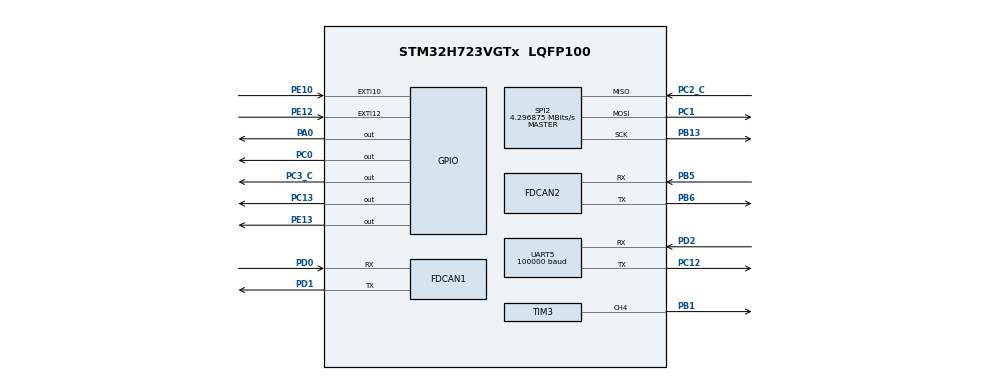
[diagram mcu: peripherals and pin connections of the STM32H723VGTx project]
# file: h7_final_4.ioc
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CORTEX_M7.default_mode_Activation=0
Dma.Request0=UART5_RX
Dma.Request1=SPI2_TX
Dma.Request2=SPI2_RX
Dma.SPI2_RX.2.Direction=DMA_PERIPH_TO_MEMORY
Dma.SPI2_RX.2.EventEnable=DISABLE
Dma.SPI2_RX.2.FIFOMode=DMA_FIFOMODE_DISABLE
Dma.SPI2_RX.2.Instance=DMA1_Stream2
Dma.SPI2_RX.2.MemDataAlignment=DMA_MDATAALIGN_BYTE
Dma.SPI2_RX.2.MemInc=DMA_MINC_ENABLE
Dma.SPI2_RX.2.Mode=DMA_NORMAL
Dma.SPI2_RX.2.PeriphDataAlignment=DMA_PDATAALIGN_BYTE
Dma.SPI2_RX.2.PeriphInc=DMA_PINC_DISABLE
Dma.SPI2_RX.2.Polarity=HAL_DMAMUX_REQ_GEN_RISING
Dma.SPI2_RX.2.Priority=DMA_PRIORITY_LOW
Dma.SPI2_RX.2.RequestNumber=1
Dma.SPI2_RX.2.SignalID=NONE
Dma.SPI2_RX.2.SyncEnable=DISABLE
Dma.SPI2_RX.2.SyncPolarity=HAL_DMAMUX_SYNC_NO_EVENT
Dma.SPI2_RX.2.SyncRequestNumber=1
Dma.SPI2_RX.2.SyncSignalID=NONE
Dma.SPI2_TX.1.Direction=DMA_MEMORY_TO_PERIPH
Dma.SPI2_TX.1.EventEnable=DISABLE
Dma.SPI2_TX.1.FIFOMode=DMA_FIFOMODE_DISABLE
Dma.SPI2_TX.1.Instance=DMA1_Stream1
Dma.SPI2_TX.1.MemDataAlignment=DMA_MDATAALIGN_BYTE
Dma.SPI2_TX.1.MemInc=DMA_MINC_ENABLE
Dma.SPI2_TX.1.Mode=DMA_NORMAL
Dma.SPI2_TX.1.PeriphDataAlignment=DMA_PDATAALIGN_BYTE
Dma.SPI2_TX.1.PeriphInc=DMA_PINC_DISABLE
Dma.SPI2_TX.1.Polarity=HAL_DMAMUX_REQ_GEN_RISING
Dma.SPI2_TX.1.Priority=DMA_PRIORITY_LOW
Dma.SPI2_TX.1.RequestNumber=1
Dma.SPI2_TX.1.SignalID=NONE
Dma.SPI2_TX.1.SyncEnable=DISABLE
Dma.SPI2_TX.1.SyncPolarity=HAL_DMAMUX_SYNC_NO_EVENT
Dma.SPI2_TX.1.SyncRequestNumber=1
Dma.SPI2_TX.1.SyncSignalID=NONE
Dma.UART5_RX.0.Direction=DMA_PERIPH_TO_MEMORY
Dma.UART5_RX.0.EventEnable=DISABLE
Dma.UART5_RX.0.FIFOMode=DMA_FIFOMODE_DISABLE
Dma.UART5_RX.0.Instance=DMA1_Stream0
Dma.UART5_RX.0.MemDataAlignment=DMA_MDATAALIGN_BYTE
Dma.UART5_RX.0.MemInc=DMA_MINC_ENABLE
Dma.UART5_RX.0.Mode=DMA_NORMAL
Dma.UART5_RX.0.PeriphDataAlignment=DMA_PDATAALIGN_BYTE
Dma.UART5_RX.0.PeriphInc=DMA_PINC_DISABLE
Dma.UART5_RX.0.Polarity=HAL_DMAMUX_REQ_GEN_RISING
Dma.UART5_RX.0.Priority=DMA_PRIORITY_LOW
Dma.UART5_RX.0.RequestNumber=1
Dma.UART5_RX.0.SignalID=NONE
Dma.UART5_RX.0.SyncEnable=DISABLE
Dma.UART5_RX.0.SyncPolarity=HAL_DMAMUX_SYNC_NO_EVENT
Dma.UART5_RX.0.SyncRequestNumber=1
Dma.UART5_RX.0.SyncSignalID=NONE
FDCAN1.CalculateBaudRateNominal=1000000
FDCAN1.CalculateTimeBitNominal=1000
FDCAN1.CalculateTimeQuantumNominal=50.0
FDCAN1.DataPrescaler=3
FDCAN1.DataSyncJumpWidth=5
FDCAN1.DataTimeSeg1=14
FDCAN1.DataTimeSeg2=5
FDCAN1.NominalPrescaler=3
FDCAN1.NominalSyncJumpWidth=5
FDCAN1.NominalTimeSeg1=14
FDCAN1.NominalTimeSeg2=5
FDCAN1.ProtocolException=ENABLE
FDCAN1.RxFifo0ElmtsNbr=4
FDCAN1.StdFiltersNbr=1
FDCAN1.TxFifoQueueElmtsNbr=2
FDCAN2.CalculateBaudRateNominal=1000000
FDCAN2.CalculateTimeBitNominal=1000
FDCAN2.CalculateTimeQuantumNominal=50.0
FDCAN2.DataPrescaler=3
FDCAN2.DataSyncJumpWidth=5
FDCAN2.DataTimeSeg1=14
FDCAN2.DataTimeSeg2=5
FDCAN2.MessageRAMOffset=1280
FDCAN2.NominalPrescaler=3
FDCAN2.NominalSyncJumpWidth=5
FDCAN2.NominalTimeSeg1=5
FDCAN2.NominalTimeSeg2=14
FDCAN2.RxFifo0ElmtsNbr=4
FDCAN2.StdFiltersNbr=1
FDCAN2.TxFifoQueueElmtsNbr=2
FREERTOS.Tasks01=defaultTask,24,128,StartDefaultTask,As weak,NULL,Dynamic,NULL,NULL;TaskPTZ02,8,512,PTZTask02,As weak,NULL,Dynamic,NULL,NULL;TaskChassis03,8,512,ChassisTask03,As weak,NULL,Dynamic,NULL,NULL;TaskCan04,8,1024,CanTask04,As weak,NULL,Dynamic,NULL,NULL;TaskPowermeter0,8,128,PowermeterTask05,As weak,NULL,Dynamic,NULL,NULL;TaskSwitch06,8,128,SwtichTask06,As weak,NULL,Dynamic,NULL,NULL;TaskIMU07,40,512,IMU_task,As weak,NULL,Dynamic,NULL,NULL
Mcu.Family=STM32H7
Mcu.Name=STM32H723VGTx
Mcu.Package=LQFP100
NVIC.DMA1_Stream0_IRQn=true\:5\:0\:false\:false\:true\:true\:false\:true\:true
NVIC.DMA1_Stream1_IRQn=true\:5\:0\:false\:false\:true\:true\:false\:true\:true
NVIC.DMA1_Stream2_IRQn=true\:5\:0\:false\:false\:true\:true\:false\:true\:true
NVIC.EXTI15_10_IRQn=true\:5\:0\:false\:false\:true\:false\:true\:true\:true
NVIC.FDCAN1_IT0_IRQn=true\:5\:0\:false\:false\:true\:true\:true\:true\:true
NVIC.FDCAN1_IT1_IRQn=true\:5\:0\:false\:false\:true\:true\:true\:true\:true
NVIC.FDCAN2_IT0_IRQn=true\:5\:0\:false\:false\:true\:true\:true\:true\:true
NVIC.FDCAN2_IT1_IRQn=true\:5\:0\:false\:false\:true\:true\:true\:true\:true
NVIC.FDCAN_CAL_IRQn=true\:5\:0\:false\:false\:true\:true\:true\:true\:true
NVIC.PriorityGroup=NVIC_PRIORITYGROUP_4
NVIC.SPI2_IRQn=true\:5\:0\:false\:false\:true\:true\:false\:true\:true
NVIC.TIM2_IRQn=true\:15\:0\:false\:false\:true\:false\:false\:true\:true
NVIC.TimeBase=TIM2_IRQn
NVIC.TimeBaseIP=TIM2
NVIC.UART5_IRQn=true\:5\:0\:false\:false\:true\:true\:true\:true\:true
PA0.Signal=GPIO_Output
PA13(JTMS/SWDIO).Mode=Serial_Wire
PA13(JTMS/SWDIO).Signal=DEBUG_JTMS-SWDIO
PA14(JTCK/SWCLK).Mode=Serial_Wire
PA14(JTCK/SWCLK).Signal=DEBUG_JTCK-SWCLK
PB1.Signal=S_TIM3_CH4
PB13.Mode=Full_Duplex_Master
PB13.Signal=SPI2_SCK
PB5.Mode=FDCAN_Activate
PB5.Signal=FDCAN2_RX
PB6.Mode=FDCAN_Activate
PB6.Signal=FDCAN2_TX
PC0.Signal=GPIO_Output
PC1.Mode=Full_Duplex_Master
PC1.Signal=SPI2_MOSI
PC12.Mode=Asynchronous
PC12.Signal=UART5_TX
PC13.Signal=GPIO_Output
PC2_C.Mode=Full_Duplex_Master
PC2_C.Signal=SPI2_MISO
PC3_C.Signal=GPIO_Output
PD0.Mode=FDCAN_Activate
PD0.Signal=FDCAN1_RX
PD1.Mode=FDCAN_Activate
PD1.Signal=FDCAN1_TX
PD2.Mode=Asynchronous
PD2.Signal=UART5_RX
PE10.Signal=GPXTI10
PE12.Signal=GPXTI12
PE13.Signal=GPIO_Output
PH0-OSC_IN.Mode=HSE-External-Oscillator
PH0-OSC_IN.Signal=RCC_OSC_IN
PH1-OSC_OUT.Mode=HSE-External-Oscillator
PH1-OSC_OUT.Signal=RCC_OSC_OUT
ProjectManager.HeapSize=0x200
ProjectManager.StackSize=0x400
ProjectManager.TargetToolchain=MDK-ARM V5.32
RCC.ADCFreq_Value=90000000
RCC.APB1Freq_Value=137500000
RCC.APB2Freq_Value=137500000
RCC.APB3Freq_Value=137500000
RCC.APB4Freq_Value=137500000
RCC.CortexFreq_Value=550000000
RCC.D1PPRE=RCC_APB3_DIV2
RCC.D2PPRE1=RCC_APB1_DIV2
RCC.D2PPRE2=RCC_APB2_DIV2
RCC.D3PPRE=RCC_APB4_DIV2
RCC.DIVM1=3
RCC.DIVM2=16
RCC.DIVN1=68
RCC.DIVN2=120
RCC.DIVP1=1
RCC.DIVQ1=4
RCC.DIVQ2=3
RCC.FDCANCLockSelection=RCC_FDCANCLKSOURCE_PLL2
RCC.HCLKFreq_Value=275000000
RCC.HPRE=RCC_HCLK_DIV2
RCC.HSE_VALUE=24000000
RCC.PLLFRACN=6144
RCC.PLLSourceVirtual=RCC_PLLSOURCE_HSE
RCC.SYSCLKFreq_VALUE=550000000
RCC.SYSCLKSource=RCC_SYSCLKSOURCE_PLLCLK
RCC.USBFreq_Value=137500000
SH.S_TIM3_CH4.0=TIM3_CH4,PWM Generation4 CH4
SPI2.BaudRatePrescaler=SPI_BAUDRATEPRESCALER_32
SPI2.CLKPhase=SPI_PHASE_2EDGE
SPI2.CLKPolarity=SPI_POLARITY_HIGH
SPI2.CalculateBaudRate=4.296875 MBits/s
SPI2.DataSize=SPI_DATASIZE_8BIT
SPI2.Direction=SPI_DIRECTION_2LINES
SPI2.Mode=SPI_MODE_MASTER
SPI2.VirtualType=VM_MASTER
TIM3.AutoReloadPreload=TIM_AUTORELOAD_PRELOAD_ENABLE
TIM3.Channel-PWM\ Generation4\ CH4=TIM_CHANNEL_4
TIM3.Period=1000-1
TIM3.Prescaler=24-1
TIM6.Prescaler=549
UART5.BaudRate=100000
UART5.Parity=PARITY_EVEN
UART5.StopBits=UART_STOPBITS_2
UART5.WordLength=WORDLENGTH_9B
VP_FREERTOS_VS_CMSIS_V2.Mode=CMSIS_V2
VP_MEMORYMAP_VS_MEMORYMAP.Mode=CurAppReg
VP_SYS_VS_tim2.Mode=TIM2
VP_TIM6_VS_ClockSourceINT.Mode=Enable_Timer
board=custom

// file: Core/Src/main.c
/* USER CODE BEGIN Header */
/**
  ******************************************************************************
  * @file           : main.c
  * @brief          : Main program body
  ******************************************************************************
  * @attention
  *
  * Copyright (c) 2026 STMicroelectronics.
  * All rights reserved.
  *
  * This software is licensed under terms that can be found in the LICENSE file
  * in the root directory of this software component.
  * If no LICENSE file comes with this software, it is provided AS-IS.
  *
  ******************************************************************************
  */
/* USER CODE END Header */
#include "main.h"
#include "FreeRTOS.h"
#include "cmsis_os2.h"
#include "dma.h"
#include "fdcan.h"
#include "spi.h"
#include "tim.h"
#include "usart.h"
#include "gpio.h"

/* USER CODE BEGIN Includes */
#include "bsp_uart.h"
#include "bsp_fdcan.h"
/* USER CODE END Includes */

void SystemClock_Config(void);
void PeriphCommonClock_Config(void);
void MX_FREERTOS_Init(void);

int main(void)
{

  /* MCU Configuration--------------------------------------------------------*/

  /* Reset of all peripherals, Initializes the Flash interface and the Systick. */
  HAL_Init();

  /* Configure the system clock */
  SystemClock_Config();

  /* Configure the peripherals common clocks */
  PeriphCommonClock_Config();

  /* Initialize all configured peripherals */
  MX_GPIO_Init();
  MX_DMA_Init();
  MX_FDCAN1_Init();
  MX_FDCAN2_Init();
  MX_UART5_Init();
  MX_SPI2_Init();
  MX_TIM3_Init();
  MX_TIM6_Init();
  /* USER CODE BEGIN 2 */
uart_init_bsp(&huart5);

Fdcan_FilterInit(&hfdcan1);
Fdcan_FilterInit(&hfdcan2);
  /* USER CODE END 2 */

  /* Init scheduler */
  osKernelInitialize();  /* Call init function for freertos objects (in cmsis_os2.c) */
  MX_FREERTOS_Init();

  /* Start scheduler */
  osKernelStart();

  /* We should never get here as control is now taken by the scheduler */

  /* Infinite loop */
  while (1)
  {

  }
}

void SystemClock_Config(void)
{
  RCC_OscInitTypeDef RCC_OscInitStruct = {0};
  RCC_ClkInitTypeDef RCC_ClkInitStruct = {0};

  /** Supply configuration update enable
  */
  HAL_PWREx_ConfigSupply(PWR_LDO_SUPPLY);

  /** Configure the main internal regulator output voltage
  */
  __HAL_PWR_VOLTAGESCALING_CONFIG(PWR_REGULATOR_VOLTAGE_SCALE0);

  while(!__HAL_PWR_GET_FLAG(PWR_FLAG_VOSRDY)) {}

  /** Initializes the RCC Oscillators according to the specified parameters
  * in the RCC_OscInitTypeDef structure.
  */
  RCC_OscInitStruct.OscillatorType = RCC_OSCILLATORTYPE_HSE;
  RCC_OscInitStruct.HSEState = RCC_HSE_ON;
  RCC_OscInitStruct.PLL.PLLState = RCC_PLL_ON;
  RCC_OscInitStruct.PLL.PLLSource = RCC_PLLSOURCE_HSE;
  RCC_OscInitStruct.PLL.PLLM = 3;
  RCC_OscInitStruct.PLL.PLLN = 68;
  RCC_OscInitStruct.PLL.PLLP = 1;
  RCC_OscInitStruct.PLL.PLLQ = 4;
  RCC_OscInitStruct.PLL.PLLR = 2;
  RCC_OscInitStruct.PLL.PLLRGE = RCC_PLL1VCIRANGE_3;
  RCC_OscInitStruct.PLL.PLLVCOSEL = RCC_PLL1VCOWIDE;
  RCC_OscInitStruct.PLL.PLLFRACN = 6144;
  if (HAL_RCC_OscConfig(&RCC_OscInitStruct) != HAL_OK)
  {
    Error_Handler();
  }

  /** Initializes the CPU, AHB and APB buses clocks
  */
  RCC_ClkInitStruct.ClockType = RCC_CLOCKTYPE_HCLK|RCC_CLOCKTYPE_SYSCLK
                              |RCC_CLOCKTYPE_PCLK1|RCC_CLOCKTYPE_PCLK2
                              |RCC_CLOCKTYPE_D3PCLK1|RCC_CLOCKTYPE_D1PCLK1;
  RCC_ClkInitStruct.SYSCLKSource = RCC_SYSCLKSOURCE_PLLCLK;
  RCC_ClkInitStruct.SYSCLKDivider = RCC_SYSCLK_DIV1;
  RCC_ClkInitStruct.AHBCLKDivider = RCC_HCLK_DIV2;
  RCC_ClkInitStruct.APB3CLKDivider = RCC_APB3_DIV2;
  RCC_ClkInitStruct.APB1CLKDivider = RCC_APB1_DIV2;
  RCC_ClkInitStruct.APB2CLKDivider = RCC_APB2_DIV2;
  RCC_ClkInitStruct.APB4CLKDivider = RCC_APB4_DIV2;

  if (HAL_RCC_ClockConfig(&RCC_ClkInitStruct, FLASH_LATENCY_3) != HAL_OK)
  {
    Error_Handler();
  }
}

void PeriphCommonClock_Config(void)
{
  RCC_PeriphCLKInitTypeDef PeriphClkInitStruct = {0};

  /** Initializes the peripherals clock
  */
  PeriphClkInitStruct.PeriphClockSelection = RCC_PERIPHCLK_FDCAN;
  PeriphClkInitStruct.PLL2.PLL2M = 16;
  PeriphClkInitStruct.PLL2.PLL2N = 120;
  PeriphClkInitStruct.PLL2.PLL2P = 2;
  PeriphClkInitStruct.PLL2.PLL2Q = 3;
  PeriphClkInitStruct.PLL2.PLL2R = 2;
  PeriphClkInitStruct.PLL2.PLL2RGE = RCC_PLL2VCIRANGE_0;
  PeriphClkInitStruct.PLL2.PLL2VCOSEL = RCC_PLL2VCOMEDIUM;
  PeriphClkInitStruct.PLL2.PLL2FRACN = 0;
  PeriphClkInitStruct.FdcanClockSelection = RCC_FDCANCLKSOURCE_PLL2;
  if (HAL_RCCEx_PeriphCLKConfig(&PeriphClkInitStruct) != HAL_OK)
  {
    Error_Handler();
  }
}

void HAL_TIM_PeriodElapsedCallback(TIM_HandleTypeDef *htim)
{
  if (htim->Instance == TIM2)
  {
    HAL_IncTick();
  }
}

void Error_Handler(void)
{
  __disable_irq();
  while (1)
  {
  }
}

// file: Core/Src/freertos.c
/* USER CODE BEGIN Header */
/**
  ******************************************************************************
  * File Name          : freertos.c
  * Description        : Code for freertos applications
  ******************************************************************************
  * @attention
  *
  * Copyright (c) 2026 STMicroelectronics.
  * All rights reserved.
  *
  * This software is licensed under terms that can be found in the LICENSE file
  * in the root directory of this software component.
  * If no LICENSE file comes with this software, it is provided AS-IS.
  *
  ******************************************************************************
  */
/* USER CODE END Header */

#include "FreeRTOS.h"
#include "task.h"
#include "main.h"
#include "FreeRTOS.h"
#include "cmsis_os2.h"

/* Definitions for defaultTask */
osThreadId_t defaultTaskHandle;
const osThreadAttr_t defaultTask_attributes = {
  .name = "defaultTask",
  .stack_size = 128 * 4,
  .priority = (osPriority_t) osPriorityNormal,
};
/* Definitions for TaskPTZ02 */
osThreadId_t TaskPTZ02Handle;
const osThreadAttr_t TaskPTZ02_attributes = {
  .name = "TaskPTZ02",
  .stack_size = 512 * 4,
  .priority = (osPriority_t) osPriorityLow,
};
/* Definitions for TaskChassis03 */
osThreadId_t TaskChassis03Handle;
const osThreadAttr_t TaskChassis03_attributes = {
  .name = "TaskChassis03",
  .stack_size = 512 * 4,
  .priority = (osPriority_t) osPriorityLow,
};
/* Definitions for TaskCan04 */
osThreadId_t TaskCan04Handle;
const osThreadAttr_t TaskCan04_attributes = {
  .name = "TaskCan04",
  .stack_size = 1024 * 4,
  .priority = (osPriority_t) osPriorityLow,
};
/* Definitions for TaskPowermeter0 */
osThreadId_t TaskPowermeter0Handle;
const osThreadAttr_t TaskPowermeter0_attributes = {
  .name = "TaskPowermeter0",
  .stack_size = 128 * 4,
  .priority = (osPriority_t) osPriorityLow,
};
/* Definitions for TaskSwitch06 */
osThreadId_t TaskSwitch06Handle;
const osThreadAttr_t TaskSwitch06_attributes = {
  .name = "TaskSwitch06",
  .stack_size = 128 * 4,
  .priority = (osPriority_t) osPriorityLow,
};
/* Definitions for TaskIMU07 */
osThreadId_t TaskIMU07Handle;
const osThreadAttr_t TaskIMU07_attributes = {
  .name = "TaskIMU07",
  .stack_size = 512 * 4,
  .priority = (osPriority_t) osPriorityHigh,
};

void StartDefaultTask(void *argument);
void PTZTask02(void *argument);
void ChassisTask03(void *argument);
void CanTask04(void *argument);
void PowermeterTask05(void *argument);
void SwtichTask06(void *argument);
void IMU_task(void *argument);

void MX_FREERTOS_Init(void); /* (MISRA C 2004 rule 8.1) */

void MX_FREERTOS_Init(void) {

  /* Create the thread(s) */
  /* creation of defaultTask */
  defaultTaskHandle = osThreadNew(StartDefaultTask, NULL, &defaultTask_attributes);

  /* creation of TaskPTZ02 */
  TaskPTZ02Handle = osThreadNew(PTZTask02, NULL, &TaskPTZ02_attributes);

  /* creation of TaskChassis03 */
  TaskChassis03Handle = osThreadNew(ChassisTask03, NULL, &TaskChassis03_attributes);

  /* creation of TaskCan04 */
  TaskCan04Handle = osThreadNew(CanTask04, NULL, &TaskCan04_attributes);

  /* creation of TaskPowermeter0 */
  TaskPowermeter0Handle = osThreadNew(PowermeterTask05, NULL, &TaskPowermeter0_attributes);

  /* creation of TaskSwitch06 */
  TaskSwitch06Handle = osThreadNew(SwtichTask06, NULL, &TaskSwitch06_attributes);

  /* creation of TaskIMU07 */
  TaskIMU07Handle = osThreadNew(IMU_task, NULL, &TaskIMU07_attributes);

}

__weak void StartDefaultTask(void *argument)
{
  for(;;)
  {
    osDelay(1);
  }
}

__weak void PTZTask02(void *argument)
{
  for(;;)
  {
    osDelay(1);
  }
}

__weak void ChassisTask03(void *argument)
{
  for(;;)
  {
    osDelay(1);
  }
}

__weak void CanTask04(void *argument)
{
  for(;;)
  {
    osDelay(1);
  }
}

__weak void PowermeterTask05(void *argument)
{
  for(;;)
  {
    osDelay(1);
  }
}

__weak void SwtichTask06(void *argument)
{
  for(;;)
  {
    osDelay(1);
  }
}

__weak void IMU_task(void *argument)
{
  for(;;)
  {
    osDelay(1);
  }
}
